# STM32F303 register map
File version: 1.4
CPU: CM4 r1p0, little endian, no MPU, no FPU, 4 interrupt priority bits
Registers are 32-bit, read-write, reset 0x0 unless marked. A register's access mark holds for its fields unless they carry their own. Offsets are from the block's base; [hi:lo] are bit positions; {n}, {i} and the like mark numbered series; 'fields as' and 'values as' point back to an identical list.

## DBGMCU — Debug support
Base 0xE0042000
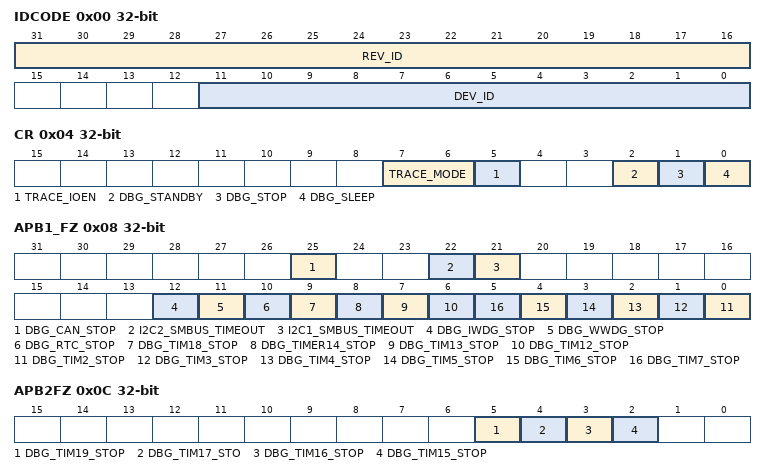
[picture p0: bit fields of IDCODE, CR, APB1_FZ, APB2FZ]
0x00 IDCODE ro — MCU Device ID Code Register
  [31:16] REV_ID — Revision Identifier
  [11:0] DEV_ID — Device Identifier
0x04 CR — Debug MCU Configuration Register
  [7:6] TRACE_MODE — Trace pin assignment control
  [5] TRACE_IOEN — Trace pin assignment control
  [2] DBG_STANDBY — Debug Standby Mode
  [1] DBG_STOP — Debug Stop Mode
  [0] DBG_SLEEP — Debug Sleep mode
0x08 APB1_FZ — APB Low Freeze Register
  [25] DBG_CAN_STOP — Debug CAN stopped when core is halted
  [22] I2C2_SMBUS_TIMEOUT — SMBUS timeout mode stopped when Core is halted
  [21] I2C1_SMBUS_TIMEOUT — SMBUS timeout mode stopped when Core is halted
  [12] DBG_IWDG_STOP — Debug Independent Wachdog stopped when Core is halted
  [11] DBG_WWDG_STOP — Debug Window Wachdog stopped when Core is halted
  [10] DBG_RTC_STOP — Debug RTC stopped when Core is halted
  [9] DBG_TIM18_STOP — Debug Timer 18 stopped when Core is halted
  [8] DBG_TIMER14_STOP — Debug Timer 14 stopped when Core is halted
  [7] DBG_TIM13_STOP — Debug Timer 13 stopped when Core is halted
  [6] DBG_TIM12_STOP — Debug Timer 12 stopped when Core is halted
  [n-2] DBG_TIM{n}_STOP (n=2..7) — Debug Timer {n} stopped when Core is halted
0x0C APB2FZ — APB High Freeze Register
  [5] DBG_TIM19_STOP — Debug Timer 19 stopped when Core is halted
  [4] DBG_TIM17_STO — Debug Timer 17 stopped when Core is halted
  [3] DBG_TIM16_STOP — Debug Timer 16 stopped when Core is halted
  [2] DBG_TIM15_STOP — Debug Timer 15 stopped when Core is halted

## FMC — Flexible memory controller
Base 0xA0000400
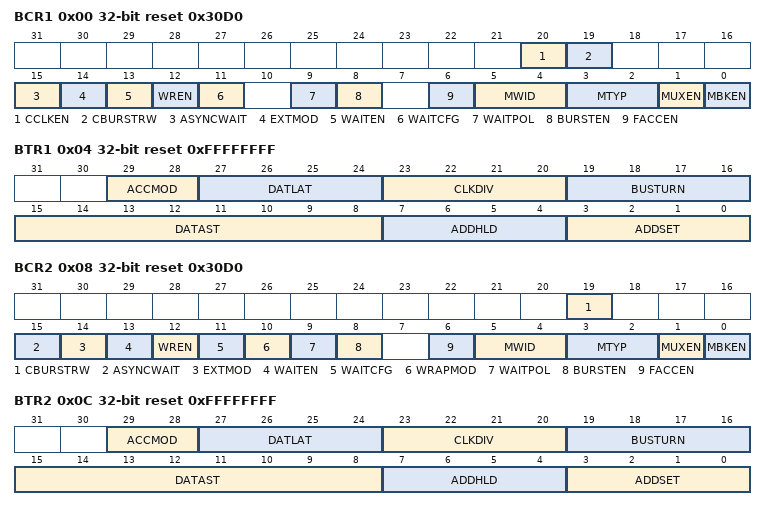
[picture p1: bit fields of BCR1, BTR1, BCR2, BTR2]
0x00 BCR1 reset 0x30D0 — SRAM/NOR-Flash chip-select control register 1
  [20] CCLKEN, [19] CBURSTRW, [15] ASYNCWAIT, [14] EXTMOD, [13] WAITEN, [12] WREN, [11] WAITCFG, [9] WAITPOL, [8] BURSTEN, [6] FACCEN, [5:4] MWID, [3:2] MTYP, [1] MUXEN, [0] MBKEN
0x04 BTR1 reset 0xFFFFFFFF — SRAM/NOR-Flash chip-select timing register 1
  [29:28] ACCMOD, [27:24] DATLAT, [23:20] CLKDIV, [19:16] BUSTURN, [15:8] DATAST, [7:4] ADDHLD, [3:0] ADDSET
0x08 BCR2 reset 0x30D0 — SRAM/NOR-Flash chip-select control register 2
  [19] CBURSTRW, [15] ASYNCWAIT, [14] EXTMOD, [13] WAITEN, [12] WREN, [11] WAITCFG, [10] WRAPMOD, [9] WAITPOL, [8] BURSTEN, [6] FACCEN, [5:4] MWID, [3:2] MTYP, [1] MUXEN, [0] MBKEN
0x0C BTR2 reset 0xFFFFFFFF — SRAM/NOR-Flash chip-select timing register 2
  fields as BTR1
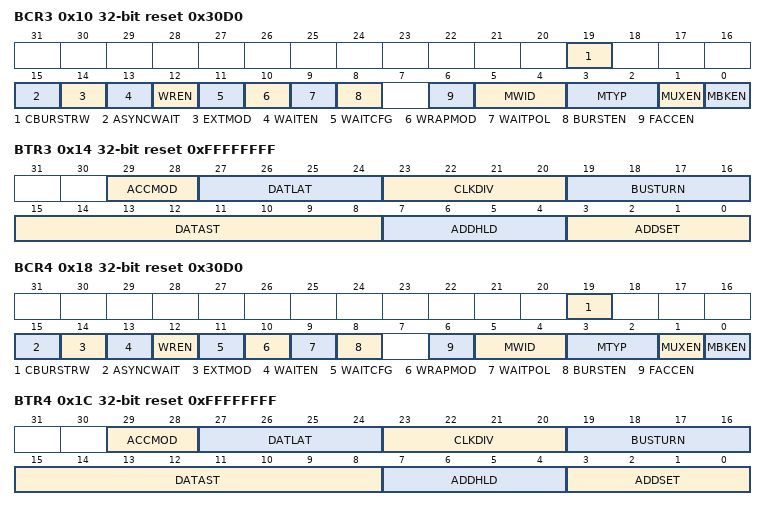
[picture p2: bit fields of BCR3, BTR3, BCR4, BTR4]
0x10 BCR3 reset 0x30D0 — SRAM/NOR-Flash chip-select control register 3
  fields as BCR2
0x14 BTR3 reset 0xFFFFFFFF — SRAM/NOR-Flash chip-select timing register 3
  fields as BTR1
0x18 BCR4 reset 0x30D0 — SRAM/NOR-Flash chip-select control register 4
  fields as BCR2
0x1C BTR4 reset 0xFFFFFFFF — SRAM/NOR-Flash chip-select timing register 4
  fields as BTR1
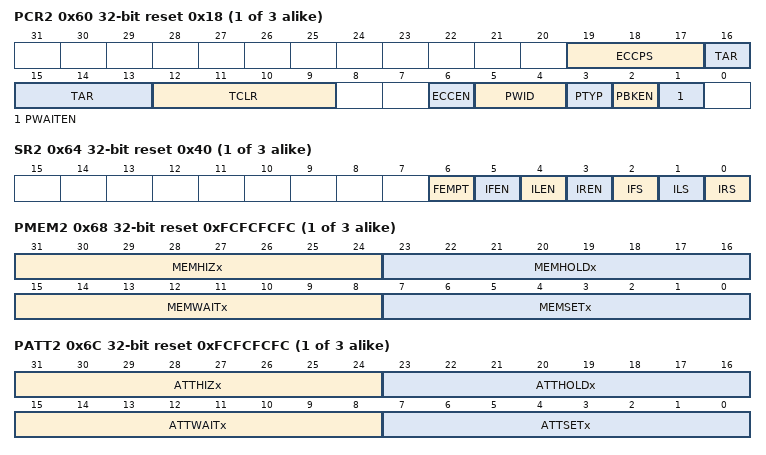
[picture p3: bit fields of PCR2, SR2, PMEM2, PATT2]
{0x20+0x20*i} PCR{i} reset 0x18 (i=2..4) — PC Card/NAND Flash control register {i}
  [19:17] ECCPS, [16:13] TAR, [12:9] TCLR, [6] ECCEN, [5:4] PWID, [3] PTYP, [2] PBKEN, [1] PWAITEN
{0x24+0x20*i} SR{i} access per field reset 0x40 (i=2..4) — FIFO status and interrupt register {i}
  [6] FEMPT ro, [5] IFEN rw, [4] ILEN rw, [3] IREN rw, [2] IFS rw, [1] ILS rw, [0] IRS rw
{0x28+0x20*i} PMEM{i} reset 0xFCFCFCFC (i=2..4) — Common memory space timing register {i}
  [31:24] MEMHIZx, [23:16] MEMHOLDx, [15:8] MEMWAITx, [7:0] MEMSETx
{0x2C+0x20*i} PATT{i} reset 0xFCFCFCFC (i=2..4) — Attribute memory space timing register {i}
  [31:24] ATTHIZx, [23:16] ATTHOLDx, [15:8] ATTWAITx, [7:0] ATTSETx
0x74 ECCR2 ro — ECC result register 2
  [31:0] ECCx
0x94 ECCR3 ro — ECC result register 3
  [31:0] ECCx
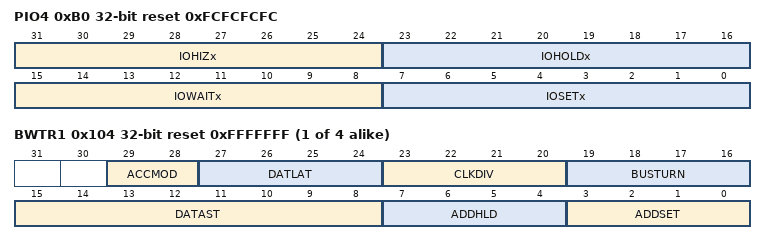
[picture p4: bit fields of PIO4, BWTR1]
0xB0 PIO4 reset 0xFCFCFCFC — I/O space timing register 4
  [31:24] IOHIZx, [23:16] IOHOLDx, [15:8] IOWAITx, [7:0] IOSETx
{0xFC+8i} BWTR{i} reset 0xFFFFFFF (i=1..4) — SRAM/NOR-Flash write timing registers {i}
  [29:28] ACCMOD
  [27:24] DATLAT
  [23:20] CLKDIV
  [19:16] BUSTURN — Bus turnaround phase duration
  [15:8] DATAST
  [7:4] ADDHLD
  [3:0] ADDSET
